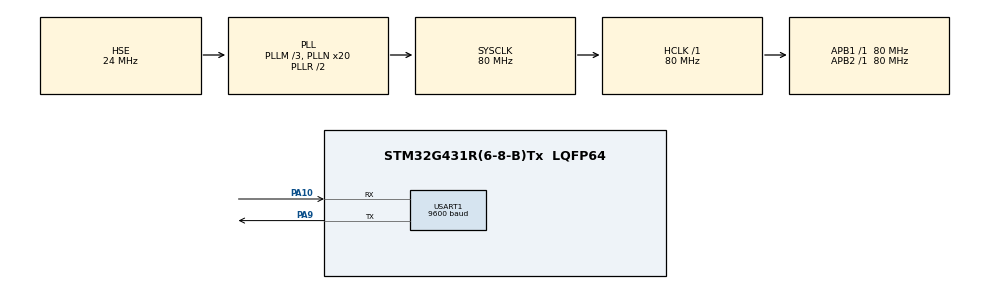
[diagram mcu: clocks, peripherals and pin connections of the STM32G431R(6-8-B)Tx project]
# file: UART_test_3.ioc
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Dma.Request0=USART1_TX
Dma.USART1_TX.0.Direction=DMA_MEMORY_TO_PERIPH
Dma.USART1_TX.0.EventEnable=DISABLE
Dma.USART1_TX.0.Instance=DMA1_Channel1
Dma.USART1_TX.0.MemDataAlignment=DMA_MDATAALIGN_BYTE
Dma.USART1_TX.0.MemInc=DMA_MINC_ENABLE
Dma.USART1_TX.0.Mode=DMA_NORMAL
Dma.USART1_TX.0.PeriphDataAlignment=DMA_PDATAALIGN_BYTE
Dma.USART1_TX.0.PeriphInc=DMA_PINC_DISABLE
Dma.USART1_TX.0.Polarity=HAL_DMAMUX_REQ_GEN_RISING
Dma.USART1_TX.0.Priority=DMA_PRIORITY_LOW
Dma.USART1_TX.0.RequestNumber=1
Dma.USART1_TX.0.SignalID=NONE
Dma.USART1_TX.0.SyncEnable=DISABLE
Dma.USART1_TX.0.SyncPolarity=HAL_DMAMUX_SYNC_NO_EVENT
Dma.USART1_TX.0.SyncRequestNumber=1
Dma.USART1_TX.0.SyncSignalID=NONE
Mcu.Family=STM32G4
Mcu.Name=STM32G431R(6-8-B)Tx
Mcu.Package=LQFP64
NVIC.DMA1_Channel1_IRQn=true\:0\:0\:false\:false\:true\:false\:true\:true
NVIC.PriorityGroup=NVIC_PRIORITYGROUP_4
NVIC.USART1_IRQn=true\:1\:0\:true\:false\:true\:true\:true\:true
PA10.Mode=Asynchronous
PA10.Signal=USART1_RX
PA9.Mode=Asynchronous
PA9.Signal=USART1_TX
PF0-OSC_IN.Mode=HSE-External-Oscillator
PF0-OSC_IN.Signal=RCC_OSC_IN
PF1-OSC_OUT.Mode=HSE-External-Oscillator
PF1-OSC_OUT.Signal=RCC_OSC_OUT
ProjectManager.HeapSize=0x200
ProjectManager.StackSize=0x400
ProjectManager.TargetToolchain=MDK-ARM V5
RCC.ADC12Freq_Value=80000000
RCC.AHBFreq_Value=80000000
RCC.APB1Freq_Value=80000000
RCC.APB1TimFreq_Value=80000000
RCC.APB2Freq_Value=80000000
RCC.APB2TimFreq_Value=80000000
RCC.CortexFreq_Value=80000000
RCC.EXTERNAL_CLOCK_VALUE=12288000
RCC.HCLKFreq_Value=80000000
RCC.HSE_VALUE=24000000
RCC.HSI48_VALUE=48000000
RCC.HSI_VALUE=16000000
RCC.LSE_VALUE=32768
RCC.PLLM=RCC_PLLM_DIV3
RCC.PLLN=20
RCC.PLLSourceVirtual=RCC_PLLSOURCE_HSE
RCC.SYSCLKFreq_VALUE=80000000
RCC.SYSCLKSource=RCC_SYSCLKSOURCE_PLLCLK
RCC.USBFreq_Value=80000000
RCC.VCOOutputFreq_Value=160000000
USART1.BaudRate=9600
USART1.VirtualMode-Asynchronous=VM_ASYNC
VP_SYS_VS_DBSignals.Mode=DisableDeadBatterySignals
board=custom

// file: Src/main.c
/* USER CODE BEGIN Header */
/**
  ******************************************************************************
  * @file           : main.c
  * @brief          : Main program body
  ******************************************************************************
  * @attention
  *
  * Copyright (c) 2025 STMicroelectronics.
  * All rights reserved.
  *
  * This software is licensed under terms that can be found in the LICENSE file
  * in the root directory of this software component.
  * If no LICENSE file comes with this software, it is provided AS-IS.
  *
  ******************************************************************************
  */
/* USER CODE END Header */
#include "main.h"
#include "dma.h"
#include "usart.h"
#include "gpio.h"

/* USER CODE BEGIN PD */
uint8_t str[30];
uint8_t a = 0;

uint8_t rx_buffer;
uint8_t rx_value[30];  //存放接收到的数据
uint8_t rx_counter=0;   //接收数据指针
/* USER CODE END PD */

void SystemClock_Config(void);

/* USER CODE BEGIN 0 */

uint32_t uart_uwTick = 0;
void URAT_Pro()
{
	if(uwTick - uart_uwTick < 100) return;
		uart_uwTick = uwTick;

	if(rx_counter != 0)//串口开始接收数据
	{
		if(rx_value[rx_counter] == '\0')  //判断串口数据是否接收完毕
		{
			if(rx_value[0] == '1')
			{
				printf("first_is_1");
			}
			else
			{
				printf("first_is_not_1");
			}
		}

		rx_counter = 0;
		memset(rx_value, 0, 30);
	}
}

/* USER CODE END 0 */

int main(void)
{

  /* MCU Configuration--------------------------------------------------------*/

  /* Reset of all peripherals, Initializes the Flash interface and the Systick. */
  HAL_Init();

  /* Configure the system clock */
  SystemClock_Config();

  /* Initialize all configured peripherals */
  MX_GPIO_Init();
  MX_DMA_Init();
  MX_USART1_UART_Init();
  /* USER CODE BEGIN 2 */

	HAL_UART_Receive_IT(&huart1, &rx_buffer, 1);//接收的是rx_buffer，然后在回调函数里面把rx_buffer的值赋给了rx_value这个数组，
//	__HAL_UART_ENABLE_IT(&huart1, UART_IT_IDLE);
//	HAL_UARTEx_ReceiveToIdle_IT(&huart1, rx_value, 30);

  /* USER CODE END 2 */

  /* Infinite loop */
  /* USER CODE BEGIN WHILE */
  while (1)
  {
		//HAL库函数发送
//		sprintf((char *)str, "hello:%d\r\n",a);
//		HAL_UART_Transmit(&huart1, str, strlen((char *)str), 50);
		//DMA方式发送
//		HAL_UART_Transmit_DMA(&huart1, str, strlen((char *)str));
		//printf发送
//		printf("hello:%d",a);
//		HAL_Delay(1000);
//		a++;

		URAT_Pro();
    /* USER CODE END WHILE */

  }
}

void SystemClock_Config(void)
{
  RCC_OscInitTypeDef RCC_OscInitStruct = {0};
  RCC_ClkInitTypeDef RCC_ClkInitStruct = {0};

  /** Configure the main internal regulator output voltage
  */
  HAL_PWREx_ControlVoltageScaling(PWR_REGULATOR_VOLTAGE_SCALE1);

  /** Initializes the RCC Oscillators according to the specified parameters
  * in the RCC_OscInitTypeDef structure.
  */
  RCC_OscInitStruct.OscillatorType = RCC_OSCILLATORTYPE_HSE;
  RCC_OscInitStruct.HSEState = RCC_HSE_ON;
  RCC_OscInitStruct.PLL.PLLState = RCC_PLL_ON;
  RCC_OscInitStruct.PLL.PLLSource = RCC_PLLSOURCE_HSE;
  RCC_OscInitStruct.PLL.PLLM = RCC_PLLM_DIV3;
  RCC_OscInitStruct.PLL.PLLN = 20;
  RCC_OscInitStruct.PLL.PLLP = RCC_PLLP_DIV2;
  RCC_OscInitStruct.PLL.PLLQ = RCC_PLLQ_DIV2;
  RCC_OscInitStruct.PLL.PLLR = RCC_PLLR_DIV2;
  if (HAL_RCC_OscConfig(&RCC_OscInitStruct) != HAL_OK)
  {
    Error_Handler();
  }

  /** Initializes the CPU, AHB and APB buses clocks
  */
  RCC_ClkInitStruct.ClockType = RCC_CLOCKTYPE_HCLK|RCC_CLOCKTYPE_SYSCLK
                              |RCC_CLOCKTYPE_PCLK1|RCC_CLOCKTYPE_PCLK2;
  RCC_ClkInitStruct.SYSCLKSource = RCC_SYSCLKSOURCE_PLLCLK;
  RCC_ClkInitStruct.AHBCLKDivider = RCC_SYSCLK_DIV1;
  RCC_ClkInitStruct.APB1CLKDivider = RCC_HCLK_DIV1;
  RCC_ClkInitStruct.APB2CLKDivider = RCC_HCLK_DIV1;

  if (HAL_RCC_ClockConfig(&RCC_ClkInitStruct, FLASH_LATENCY_2) != HAL_OK)
  {
    Error_Handler();
  }
}

/* USER CODE BEGIN 4 */
void HAL_UART_RxCpltCallback(UART_HandleTypeDef *huart)
{
//	HAL_UART_Transmit(&huart1, &rx_buffer, 1, 50);
	//每收到一个字节，进入该中断回调函数
	rx_value[rx_counter++] = rx_buffer;

	HAL_UART_Receive_IT(&huart1, &rx_buffer, 1);
}

//空闲中断接收回调
//void HAL_UARTEx_RxEventCallback(UART_HandleTypeDef *huart, uint16_t Size)
//{
//	if(huart->Instance == USART1)
//	{
////		HAL_UART_Transmit(&huart1, rx_value, strlen((char *)rx_value), 50);
//		//收到的数据第一位是1，向串口发送"first_is_1"
//		if(rx_value[0] == '1')
//		{
//			printf("first_is_1");
//		}
//
//		memset(rx_value, 0, sizeof(rx_value));
//
//		HAL_UARTEx_ReceiveToIdle_IT(&huart1, rx_value, 30);
//	}
//
//}

/* USER CODE END 4 */

void Error_Handler(void)
{
  __disable_irq();
  while (1)
  {
  }
}
